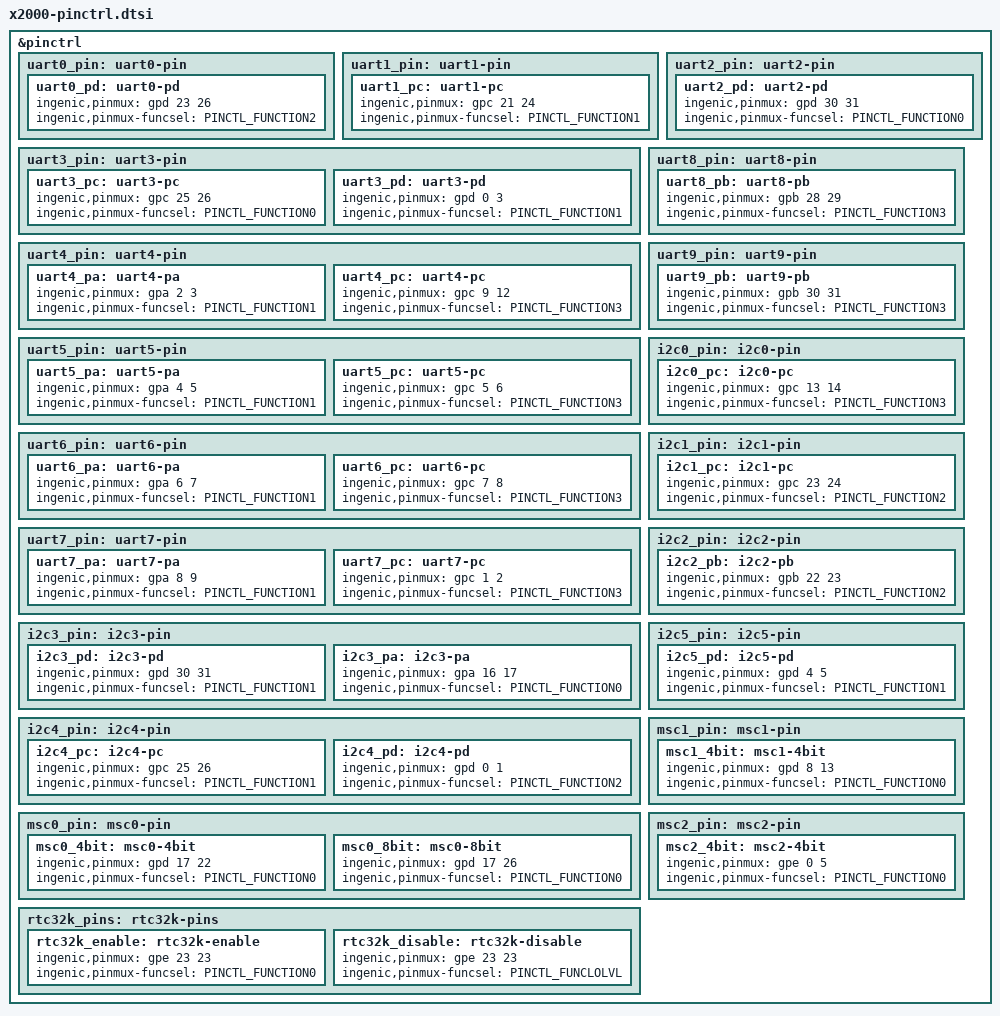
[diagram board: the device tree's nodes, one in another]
// SPDX-License-Identifier: GPL-2.0
/*
 * Pin groups of the Ingenic X2000 for the SDK's pin control driver: from the
 * SDK kernel 6.6 (module_drivers/dts/x2000/x2000-pinctrl.dtsi), the groups of
 * the blocks x2000.dtsi describes.
 */

#include <dt-bindings/pinctrl/ingenic-pinctrl.h>

&pinctrl {
	uart0_pin: uart0-pin {
		uart0_pd: uart0-pd {
			ingenic,pinmux = <&gpd 23 26>;
			ingenic,pinmux-funcsel = <PINCTL_FUNCTION2>;
		};
	};
	uart1_pin: uart1-pin {
		uart1_pc: uart1-pc {
			ingenic,pinmux = <&gpc 21 24>;
			ingenic,pinmux-funcsel = <PINCTL_FUNCTION1>;
		};
	};

	uart2_pin: uart2-pin {
		uart2_pd: uart2-pd {
			ingenic,pinmux = <&gpd 30 31>;
			ingenic,pinmux-funcsel = <PINCTL_FUNCTION0>;
		};
	};

	uart3_pin: uart3-pin {
		uart3_pc: uart3-pc {
			ingenic,pinmux = <&gpc 25 26>;
			ingenic,pinmux-funcsel = <PINCTL_FUNCTION0>;
		};
		uart3_pd: uart3-pd {
			ingenic,pinmux = <&gpd 0 3>;
			ingenic,pinmux-funcsel = <PINCTL_FUNCTION1>;
		};
	};

	uart4_pin: uart4-pin {
		uart4_pa: uart4-pa {
			/*
			 * RX and TX. The SDK had PA0 to PA3 here; PA1 switches
			 * the supply of the K1's Wi-Fi module, and the K1's
			 * stock device tree has pins 2 and 3 alone.
			 */
			ingenic,pinmux = <&gpa 2 3>;
			ingenic,pinmux-funcsel = <PINCTL_FUNCTION1>;
		};
		uart4_pc: uart4-pc {
			ingenic,pinmux = <&gpc 9 12>;
			ingenic,pinmux-funcsel = <PINCTL_FUNCTION3>;
		};
	};

	uart5_pin: uart5-pin {
		uart5_pa: uart5-pa {
			ingenic,pinmux = <&gpa 4 5>;
			ingenic,pinmux-funcsel = <PINCTL_FUNCTION1>;
		};
		uart5_pc: uart5-pc {
			ingenic,pinmux = <&gpc 5 6>;
			ingenic,pinmux-funcsel = <PINCTL_FUNCTION3>;
		};
	};

	uart6_pin: uart6-pin {
		uart6_pa: uart6-pa {
			ingenic,pinmux = <&gpa 6 7>;
			ingenic,pinmux-funcsel = <PINCTL_FUNCTION1>;
		};
		uart6_pc: uart6-pc {
			ingenic,pinmux = <&gpc 7 8>;
			ingenic,pinmux-funcsel = <PINCTL_FUNCTION3>;
		};
	};

	uart7_pin: uart7-pin {
		uart7_pa: uart7-pa {
			ingenic,pinmux = <&gpa 8 9>;
			ingenic,pinmux-funcsel = <PINCTL_FUNCTION1>;
		};
		uart7_pc: uart7-pc {
			ingenic,pinmux = <&gpc 1 2>;
			ingenic,pinmux-funcsel = <PINCTL_FUNCTION3>;
		};
	};

	uart8_pin: uart8-pin {
		uart8_pb: uart8-pb {
			ingenic,pinmux = <&gpb 28 29>;
			ingenic,pinmux-funcsel = <PINCTL_FUNCTION3>;
		};
	};

	uart9_pin: uart9-pin {
		uart9_pb: uart9-pb {
			ingenic,pinmux = <&gpb 30 31>;
			ingenic,pinmux-funcsel = <PINCTL_FUNCTION3>;
		};
	};

	i2c0_pin: i2c0-pin {
		i2c0_pc: i2c0-pc {
			ingenic,pinmux = <&gpc 13 14>;
			ingenic,pinmux-funcsel = <PINCTL_FUNCTION3>;
		};
	};

	i2c1_pin: i2c1-pin {
		i2c1_pc: i2c1-pc {
			ingenic,pinmux = <&gpc 23 24>;
			ingenic,pinmux-funcsel = <PINCTL_FUNCTION2>;
		};
	};

	i2c2_pin: i2c2-pin {
		i2c2_pb: i2c2-pb {
			ingenic,pinmux = <&gpb 22 23>;
			ingenic,pinmux-funcsel = <PINCTL_FUNCTION2>;
		};
	};

	i2c3_pin: i2c3-pin {
		i2c3_pd: i2c3-pd {
			ingenic,pinmux = <&gpd 30 31>;
			ingenic,pinmux-funcsel = <PINCTL_FUNCTION1>;
		};
		i2c3_pa: i2c3-pa {
			ingenic,pinmux = <&gpa 16 17>;
			ingenic,pinmux-funcsel = <PINCTL_FUNCTION0>;
		};
	};

	i2c4_pin: i2c4-pin {
		i2c4_pc: i2c4-pc {
			ingenic,pinmux = <&gpc 25 26>;
			ingenic,pinmux-funcsel = <PINCTL_FUNCTION1>;
		};
		i2c4_pd: i2c4-pd {
			ingenic,pinmux = <&gpd 0 1>;
			ingenic,pinmux-funcsel = <PINCTL_FUNCTION2>;
		};
	};

	i2c5_pin: i2c5-pin {
		i2c5_pd: i2c5-pd {
			ingenic,pinmux = <&gpd 4 5>;
			ingenic,pinmux-funcsel = <PINCTL_FUNCTION1>;
		};
	};

	msc0_pin: msc0-pin {
		msc0_4bit: msc0-4bit {
			ingenic,pinmux = <&gpd 17 22>;
			ingenic,pinmux-funcsel = <PINCTL_FUNCTION0>;
		};
		msc0_8bit: msc0-8bit {
			ingenic,pinmux = <&gpd 17 26>;
			ingenic,pinmux-funcsel = <PINCTL_FUNCTION0>;
		};
	};

	msc1_pin: msc1-pin {
		msc1_4bit: msc1-4bit {
			ingenic,pinmux = <&gpd 8 13>;
			ingenic,pinmux-funcsel = <PINCTL_FUNCTION0>;
		};
	};

	msc2_pin: msc2-pin {
		msc2_4bit: msc2-4bit {
			ingenic,pinmux = <&gpe 0 5>;
			ingenic,pinmux-funcsel = <PINCTL_FUNCTION0>;
		};
	};

	rtc32k_pins:rtc32k-pins {
		rtc32k_enable:rtc32k-enable {
			ingenic,pinmux = <&gpe 23 23>;
			ingenic,pinmux-funcsel = <PINCTL_FUNCTION0>;
		};
		rtc32k_disable:rtc32k-disable {
			ingenic,pinmux = <&gpe 23 23>;
			ingenic,pinmux-funcsel = <PINCTL_FUNCLOLVL>;
		};
	};
};
